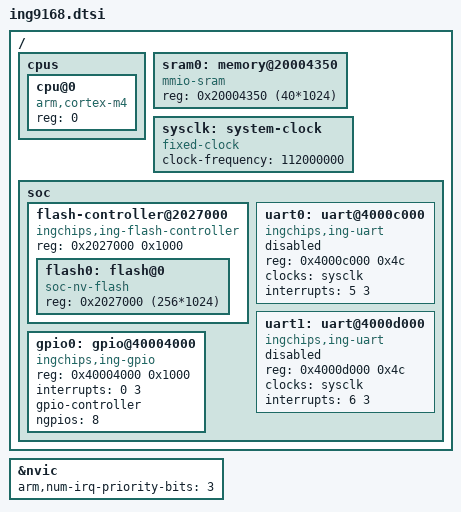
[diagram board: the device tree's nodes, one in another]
/* SPDX-License-Identifier: Apache-2.0 */

#include <arm/armv7-m.dtsi>

/ {
	cpus {
		#address-cells = <1>;
		#size-cells = <0>;

		cpu@0 {
			device_type = "cpu";
			compatible = "arm,cortex-m4";
			reg = <0>;
		};
	};

	sram0: memory@20004350 {
		compatible = "mmio-sram";
		reg = <0x20004350 (40*1024)>;
	};

	sysclk: system-clock {
		compatible = "fixed-clock";
		clock-frequency = <112000000>;
		#clock-cells = <0>;
	};

	soc {

		flash-controller@2027000 {
			compatible = "ingchips,ing-flash-controller";
			reg = <0x2027000 0x1000>;
			#address-cells = <1>;
			#size-cells = <1>;

			flash0: flash@0 {
				compatible = "soc-nv-flash";
				reg = <0x2027000 (256*1024)>;
			};
		};

		uart0: uart@4000c000 {
			compatible = "ingchips,ing-uart";
			reg = <0x4000c000 0x4c>;
			clocks = <&sysclk>;
			interrupts = <5 3>;
			status = "disabled";
		};

		uart1: uart@4000d000 {
			compatible = "ingchips,ing-uart";
			reg = <0x4000d000 0x4c>;
			clocks = <&sysclk>;
			interrupts = <6 3>;
			status = "disabled";
		};

		gpio0: gpio@40004000 {
			compatible = "ingchips,ing-gpio";
			reg = <0x40004000 0x1000>;
			interrupts = <0 3>;
			gpio-controller;
			#gpio-cells = <2>;
			ngpios = <8>;
		};

	};
};

&nvic {
	arm,num-irq-priority-bits = <3>;
};
